# AC784x register map
Vendor: AutoChips; Series: AC78; File version: 1.0
CPU: CM4 r0p1, little endian, MPU, FPU, VTOR, 4 interrupt priority bits
Registers are 32-bit, read-write, reset 0x0 unless marked. A register's access mark holds for its fields unless they carry their own. Offsets are from the block's base; [hi:lo] are bit positions; {n}, {i} and the like mark numbered series; 'fields as' and 'values as' point back to an identical list.

## SPM — System Power Manage
Base 0x40008000
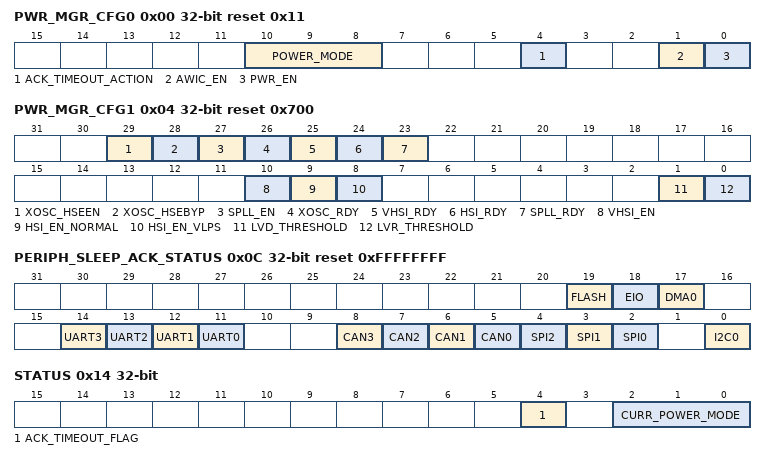
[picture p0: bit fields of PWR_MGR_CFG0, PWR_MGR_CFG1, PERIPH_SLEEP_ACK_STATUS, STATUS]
0x00 PWR_MGR_CFG0 reset 0x11 — Power Manage Config Register 0
  [10:8] POWER_MODE — Power Mode Control
    0=RUN Mode; 1=VLPR Mode; 2=STOP1 Mode; 3=STOP2 Mode; 4=VLPS Mode
  [4] ACK_TIMEOUT_ACTION — Select SPM Interrupt/RESET When Occur ACK TimeOut
    0=Interrupt; 1=Reset
  [1] AWIC_EN — Enable AWIC Module
    0=Dsable; 1=Enable
  [0] PWR_EN — SPM Power Control Enable
    0=Disable; 1=Enable
0x04 PWR_MGR_CFG1 reset 0x700 — Power Manage Config Register 1
  [29] XOSC_HSEEN — Extern High-Speed Clock Enable
    0=Disable XOSC HSE; 1=Enable XOSC HSE
  [28] XOSC_HSEBYP — Extern High-Speed Clock Bypass
    0=Disable XOSC HSE Bypass; 1=Enable XOSC HSE Bypass
  [27] SPLL_EN — System PLL Enable
    0=Disable PLL; 1=Enable PLL
  [26] XOSC_RDY ro — XOSC Clock Ready Flag
    0=Not Ready; 1=Ready
  [25] VHSI_RDY ro — VHSI Ready Flag
    0=Not Ready; 1=Ready
  [24] HSI_RDY ro — HSI Ready Flag
    0=Not Ready; 1=Ready
  [23] SPLL_RDY ro — System PLL Ready Flag
    0=Not Ready; 1=Ready
  [10] VHSI_EN — VHSI Enable
    0=Disable; 1=Enable
  [9] HSI_EN_NORMAL — HSI Enable In RUN/STOP1/STOP2 Mode
    0=Disable; 1=Enable
  [8] HSI_EN_VLPS — HSI Enable In VLPS Mode
    0=Disable; 1=Enable
  [1] LVD_THRESHOLD — LVD Voltage Threshold Set
    0=VLVDL=2.9V; 1=VLVDL=4.5V
  [0] LVR_THRESHOLD — LVR Voltage Threshold Set
    0=VLVRL=2.65V; 1=VLVRL=2.22V
0x0C PERIPH_SLEEP_ACK_STATUS ro reset 0xFFFFFFFF
  [19] FLASH — FLASH ACK Status
    0=NO ACK; 1=ACK
  [18] EIO — EIO Sleep ACK Status
    0=No ACK; 1=ACK
  [17] DMA0 — DMA0 Sleep ACK Status
    0=No ACK; 1=ACK
  [n+11] UART{n} (n=0..3) — UART{n} Sleep ACK Status
    0=No ACK; 1=ACK
  [n+5] CAN{n} (n=0..3) — CAN{n} Sleep ACK Status
    0=No ACK; 1=ACK
  [4] SPI2 — SPI2 Sleep ACK Status
    0=No ACK; 1=ACK
  [3] SPI1 — SPI1 Sleep ACK Status
    0=No ACK; 1=ACK
  [2] SPI0 — SPI0 Sleep ACK Status
    0=No ACK; 1=ACK
  [0] I2C0 — I2C0 Sleep ACK Status
    0=No ACK; 1=ACK
0x14 STATUS
  [4] ACK_TIMEOUT_FLAG — Peripheral Sleep Ack TimeOut Flag
    0=Invalid; 1=Valid
  [2:0] CURR_POWER_MODE ro — Display Current PowerMode
    values as PWR_MGR_CFG0.POWER_MODE

## GPIOA — General Purpose Input/Output
Base 0x40085000
Same registers: GPIOB 0x40085040, GPIOC 0x40085080, GPIOD 0x400850C0, GPIOE 0x40085100
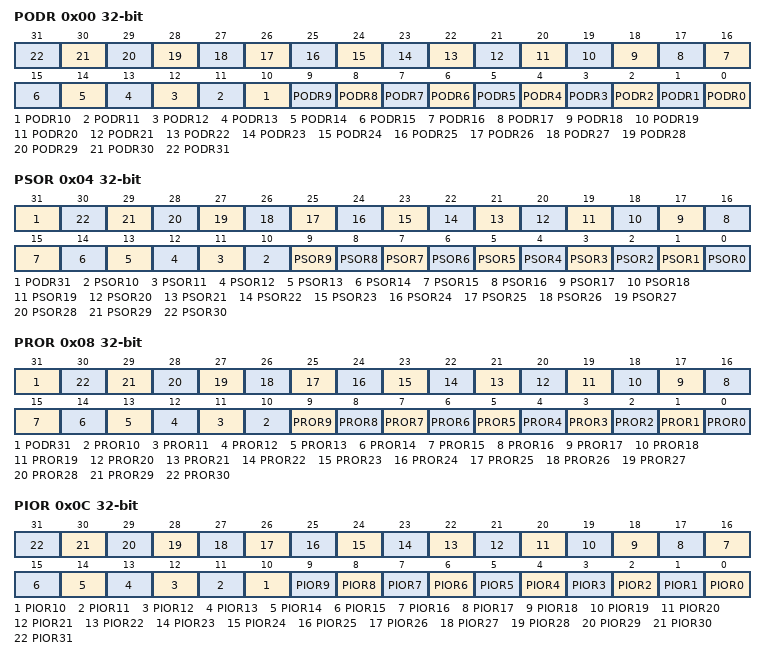
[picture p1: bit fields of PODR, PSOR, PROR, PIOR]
0x00 PODR — PORT Output Data Register
  [n] PODR{n} (n=0..31) — Port output data, bit {n}
0x04 PSOR — PORT Set Output Register
  [31] PODR31 — Port Set Output data, bit 31
  [n] PSOR{n} (n=0..30) — Port Set Output data, bit {n}
0x08 PROR — PORT Reset Output Register
  [31] PODR31 — Port Reset Output data, bit 31
  [n] PROR{n} (n=0..30) — Port Reset Output data, bit {n}
0x0C PIOR — PORT Invert Output Register
  [n] PIOR{n} (n=0..31) — Port Invert Output data, bit {n}
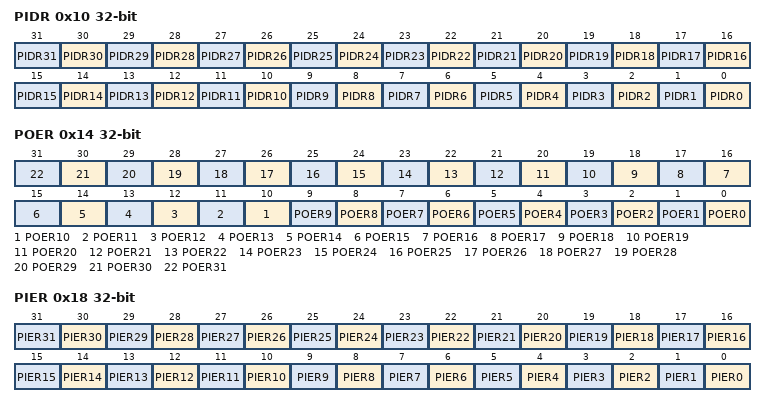
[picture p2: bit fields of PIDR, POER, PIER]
0x10 PIDR — PORT Input Data Register
  [n] PIDR{n} (n=0..31) — Port Input data, bit {n}
0x14 POER — PORT Output Enable Register
  [n] POER{n} (n=0..31) — Port Output Enable, bit {n}
0x18 PIER — PORT Input Enable Register
  [n] PIER{n} (n=0..31) — Port Input Enable, bit {n}

## ANA — Analog Control Registers
Base 0x40008800
0x50 ACMPDAC_CFG reset 0x1000000 — ACMPDAC Configuration Register
  [16] RG_MCU_ACMPDAC_LP_EN — LP mode
    1=enable; 0=disable
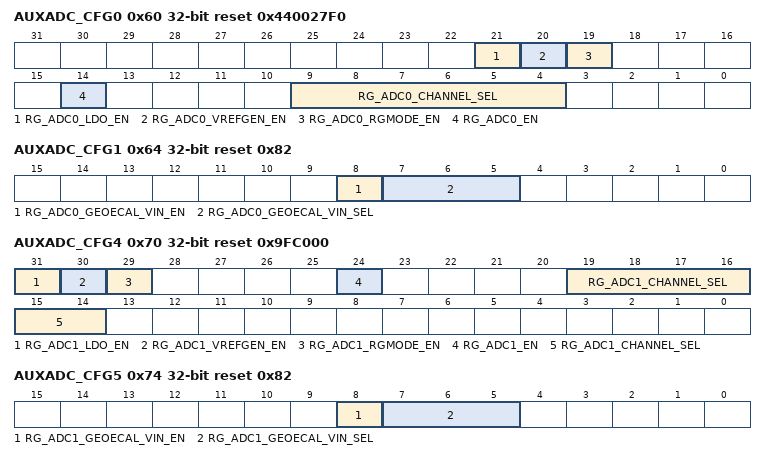
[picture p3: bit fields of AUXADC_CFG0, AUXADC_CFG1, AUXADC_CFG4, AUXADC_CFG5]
0x60 AUXADC_CFG0 reset 0x440027F0 — AUXADC Configuration Register0
  [21] RG_ADC0_LDO_EN — ADC0 LDO enable
    0=disable; 1=enable
  [20] RG_ADC0_VREFGEN_EN — ADC0 VREFGEN enable
    0=disable; 1=enable
  [19] RG_ADC0_RGMODE_EN — Registor debug mode enable
    0=normal mode, enable and channel_sel are controled by DA signal; 1=debug mode, enable and channel_sel are controled by RG signal
  [14] RG_ADC0_EN — ADC Enable
    0=disable; 1=enable
  [9:4] RG_ADC0_CHANNEL_SEL — adc input select
0x64 AUXADC_CFG1 reset 0x82 — AUXADC Configuration Register1
  [8] RG_ADC0_GEOECAL_VIN_EN — GEOE calibration enable
    0=disable; 1=enable
  [7:5] RG_ADC0_GEOECAL_VIN_SEL — GEOE calibration input voltage select
    0=Floating; 1=4*AVDD/16; 2=5*AVDD/16; 3=6*AVDD/16; 4=8*AVDD/16; 5=10*AVDD/16; 6=11*AVDD/16; 7=12*AVDD/16
0x70 AUXADC_CFG4 reset 0x9FC000 — AUXADC Configuration Register4
  [31] RG_ADC1_LDO_EN — ADC1 LDO enable
    0=disable; 1=enable
  [30] RG_ADC1_VREFGEN_EN — ADC1 VREFGEN enable
    0=disable; 1=enable
  [29] RG_ADC1_RGMODE_EN — Registor debug mode enable
    values as AUXADC_CFG0.RG_ADC0_RGMODE_EN
  [24] RG_ADC1_EN — ADC1 Enable
    0=disable; 1=enable
  [19:14] RG_ADC1_CHANNEL_SEL — adc input select
0x74 AUXADC_CFG5 reset 0x82 — AUXADC Configuration Register5
  [8] RG_ADC1_GEOECAL_VIN_EN — GEOE calibration enable
    0=disable; 1=enable
  [7:5] RG_ADC1_GEOECAL_VIN_SEL — GEOE calibration input voltage select
    values as AUXADC_CFG1.RG_ADC0_GEOECAL_VIN_SEL
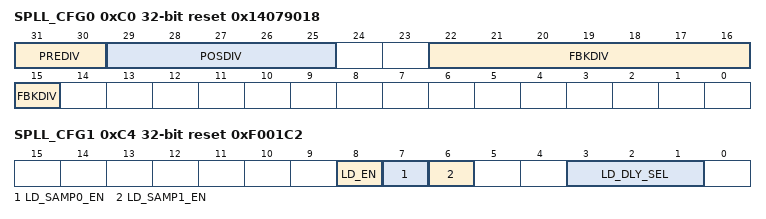
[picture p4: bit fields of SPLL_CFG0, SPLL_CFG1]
0xC0 SPLL_CFG0 reset 0x14079018 — System PLL Config 0
  [31:30] PREDIV — PLL Pre-Divider
    0=Fref=Fin/1; 1=Fref=Fin/2; 2=Fref=Fin/4; 3=Fref=Fin/4
  [29:25] POSDIV — PLL Post-divider Ratio
    0=NONE; 1=VCO/2; 2=VCO/4; 3=VCO/6; 4=VCO/8; 5=VCO/10; 6=VCO/12; 7=VCO/14; 8=VCO/16; 9=VCO/18; 10=VCO/20; 11=VCO/22; 12=VCO/24; 13=VCO/26; 14=VCO/28; 15=VCO/30; 16=VCO/32; 17=VCO/34; 18=VCO/36; 19=VCO/38; 20=VCO/40; 21=VCO/42; 22=VCO/44; 23=VCO/46; 24=VCO/48; 25=VCO/50; 26=VCO/52; 27=VCO/54; 28=VCO/56; 29=VCO/58; 30=VCO/60; 31=VCO/62
  [22:15] FBKDIV — PLL Feedback-Divider
0xC4 SPLL_CFG1 reset 0xF001C2 — System PLL Config 1
  [8] LD_EN — PLL Lock Detect Enable
    0=DISABLE; 1=ENABLE
  [7] LD_SAMP0_EN — PLL Lock Detect Sample 0 Enable
    0=DISABLE; 1=ENABLE
  [6] LD_SAMP1_EN — PLL Lock Detect Sample 1 Enable
    0=DISABLE; 1=ENABLE
  [3:1] LD_DLY_SEL — PLL Lock Detect Comparision Delay Select
    0=300ps; 1=600ps; 2=900ps; 3=1200ps; 4=2200ps; 5=3200ps; 6=4200ps; 7=5200ps
